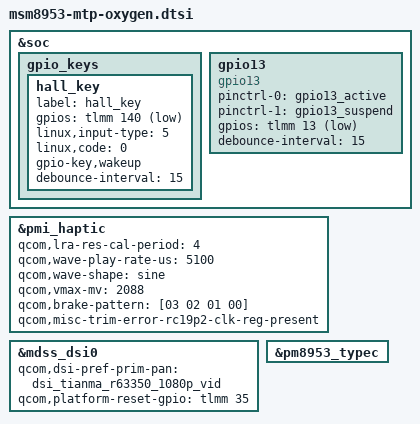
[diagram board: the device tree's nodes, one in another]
/*
 * Copyright (c) 2015-2018, The Linux Foundation. All rights reserved.
 *
 * This program is free software; you can redistribute it and/or modify
 * it under the terms of the GNU General Public License version 2 and
 * only version 2 as published by the Free Software Foundation.
 *
 * This program is distributed in the hope that it will be useful,
 * but WITHOUT ANY WARRANTY; without even the implied warranty of
 * MERCHANTABILITY or FITNESS FOR A PARTICULAR PURPOSE.  See the
 * GNU General Public License for more details.
 */

&soc {
	gpio_keys {
		hall_key {
			label = "hall_key";
			gpios = <&tlmm 140 0x01>;
			linux,input-type = <5>;
			linux,code = <0>;
			gpio-key,wakeup;
			debounce-interval = <15>;
		};
	};

	gpio13 {
		pinctrl-names = "tlmm_gpio13_active","tlmm_gpio13_suspend";
		pinctrl-0 = <&gpio13_active>;
		pinctrl-1 = <&gpio13_suspend>;
		compatible = "gpio13";
		gpios = <&tlmm 13 0x01>;
		debounce-interval = <15>;
	};
};

&pmi_haptic{
	qcom,lra-res-cal-period = <4>;
	qcom,wave-play-rate-us = <5100>;
	qcom,wave-shape = "sine";
	qcom,vmax-mv = <2088>;
	qcom,brake-pattern = [03 02 01 00];
	qcom,misc-trim-error-rc19p2-clk-reg-present;
};

&mdss_dsi0 {
	qcom,dsi-pref-prim-pan = <&dsi_tianma_r63350_1080p_vid>;
	
	qcom,platform-reset-gpio = <&tlmm 35 0>;
};

&pm8953_typec {
	/delete-property/ qcom,ssmux-gpio;
	/delete-property/ pinctrl-names;
	/delete-property/ pinctrl-0;
};

#include "msm8953-audio-mtp-oxygen.dtsi"
#include "msm8953-audio-oxygen.dtsi"
#include "msm8953-mdss-oxygen.dtsi"
#include "msm8953-mdss-panels-oxygen.dtsi"
#include "msm8953-oxygen.dtsi"
#include "msm8953-pinctrl-oxygen.dtsi"
#include "msm8953-pm-oxygen.dtsi"
#include "msm8953-regulator-oxygen.dtsi"
#include "msm-audio-oxygen.dtsi"
#include "msm-pm8953-oxygen.dtsi"
#include "msm-pmi8950-oxygen.dtsi"
#include "msm8953-oxygen-camera-sensor-mtp.dtsi"
